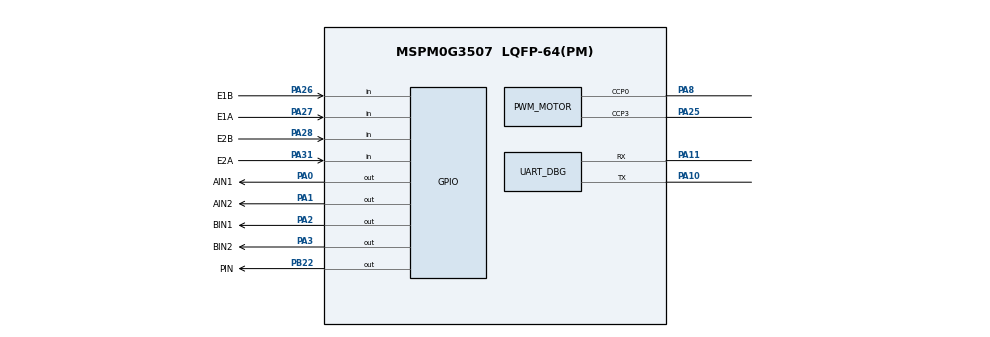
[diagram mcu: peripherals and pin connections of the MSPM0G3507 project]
/**
 * SysConfig 配置 — TB6612双路电机 + N20编码器 + UART调试
 *
 * 设备: MSPM0G350X (LQFP-64)
 *
 * 引脚分配:
 *   TB6612: PA0=AIN1, PA1=AIN2, PA2=BIN1, PA3=BIN2
 *   PWM:    TIMA0 CH0(PA8)=PWMA, TIMA0 CH3(PA25)=PWMB
 *   编码器: PA27=E1A, PA26=E1B, PA31=E2A, PA28=E2B
 *   UART:   PA10=TX, PA11=RX
 *   LED:    PB22
 */

//@cliArgs --device "MSPM0G350X" --part "Default" --package "LQFP-64(PM)"
//@v2CliArgs --device "MSPM0G3507" --package "LQFP-64(PM)"

const GPIO   = scripting.addModule("/ti/driverlib/GPIO", {}, false);
const PWM    = scripting.addModule("/ti/driverlib/PWM", {}, false);
const SYSCTL = scripting.addModule("/ti/driverlib/SYSCTL");
const TIMER  = scripting.addModule("/ti/driverlib/TIMER", {}, false);
const UART   = scripting.addModule("/ti/driverlib/UART", {}, false);

// ============================================================
// GPIO — TB6612 方向控制 (PA0~PA3)
// ============================================================
const GPIO_TB6612 = GPIO.addInstance();
GPIO_TB6612.$name = "TB6612";
GPIO_TB6612.associatedPins.create(4);
GPIO_TB6612.associatedPins[0].$name = "AIN1";
GPIO_TB6612.associatedPins[0].pin.$assign = "PA0";
GPIO_TB6612.associatedPins[1].$name = "AIN2";
GPIO_TB6612.associatedPins[1].pin.$assign = "PA1";
GPIO_TB6612.associatedPins[2].$name = "BIN1";
GPIO_TB6612.associatedPins[2].pin.$assign = "PA2";
GPIO_TB6612.associatedPins[3].$name = "BIN2";
GPIO_TB6612.associatedPins[3].pin.$assign = "PA3";

// ============================================================
// GPIO — N20编码器 (PA26~PA28, PA31) 带中断
// ============================================================
const GPIO_ENC = GPIO.addInstance();
GPIO_ENC.$name = "ENCODER";
GPIO_ENC.associatedPins.create(4);
GPIO_ENC.associatedPins[0].$name             = "E1A";
GPIO_ENC.associatedPins[0].direction         = "INPUT";
GPIO_ENC.associatedPins[0].interruptEn       = true;
GPIO_ENC.associatedPins[0].polarity          = "RISE";
GPIO_ENC.associatedPins[0].pin.$assign       = "PA27";
GPIO_ENC.associatedPins[1].$name             = "E1B";
GPIO_ENC.associatedPins[1].direction         = "INPUT";
GPIO_ENC.associatedPins[1].pin.$assign       = "PA26";
GPIO_ENC.associatedPins[2].$name             = "E2A";
GPIO_ENC.associatedPins[2].direction         = "INPUT";
GPIO_ENC.associatedPins[2].interruptEn       = true;
GPIO_ENC.associatedPins[2].polarity          = "RISE";
GPIO_ENC.associatedPins[2].pin.$assign       = "PA31";
GPIO_ENC.associatedPins[3].$name             = "E2B";
GPIO_ENC.associatedPins[3].direction         = "INPUT";
GPIO_ENC.associatedPins[3].pin.$assign       = "PA28";

// ============================================================
// GPIO — 板载LED (PB22)
// ============================================================
const GPIO_LED = GPIO.addInstance();
GPIO_LED.$name = "LED";
GPIO_LED.associatedPins.create(1);
GPIO_LED.associatedPins[0].$name = "PIN";
GPIO_LED.associatedPins[0].pin.$assign = "PB22";

// ============================================================
// PWM — TB6612电机速度 (TIMA0, 20kHz)
// ============================================================
const PWM_MOTOR = PWM.addInstance();
PWM_MOTOR.$name = "PWM_0";
PWM_MOTOR.timerStartTimer = true;
PWM_MOTOR.timerCount = 4000;     // 80MHz/4000 = 20kHz
PWM_MOTOR.clockDivider = 1;
PWM_MOTOR.ccIndex = [0, 3];      // CH0 + CH3
PWM_MOTOR.peripheral.$assign = "TIMA0";
PWM_MOTOR.peripheral.ccp0Pin.$assign = "PA8";   // PWMA
PWM_MOTOR.peripheral.ccp3Pin.$assign = "PA25";  // PWMB

// ============================================================
// Timer — 编码器采样 (TIMG0, 10ms周期中断)
// ============================================================
const TIMER_ENC = TIMER.addInstance();
TIMER_ENC.$name = "TIMER_0";
TIMER_ENC.timerMode = "PERIODIC";
TIMER_ENC.timerStartTimer = true;
TIMER_ENC.timerPeriod = "1 ms";
TIMER_ENC.timerClkDiv = 1;
TIMER_ENC.interrupts = ["ZERO"];
TIMER_ENC.interruptPriority = "2";
TIMER_ENC.peripheral.$assign = "TIMG0";

// ============================================================
// UART0 — 调试串口 (PA10=TX, PA11=RX, 115200)
// ============================================================
const UART_DBG = UART.addInstance();
UART_DBG.$name = "UART_0";
UART_DBG.targetBaudRate = 115200;
UART_DBG.peripheral.$assign = "UART0";
UART_DBG.peripheral.txPin.$assign = "PA10";
UART_DBG.peripheral.rxPin.$assign = "PA11";

// ============================================================
// SYSCTL — 系统时钟
// ============================================================
SYSCTL.forceDefaultClkConfig = true;
SYSCTL.clockTreeEn = true;

// ============================================================
// Board (必需)
// ============================================================
const Board = scripting.addModule("/ti/driverlib/Board", {}, false);
